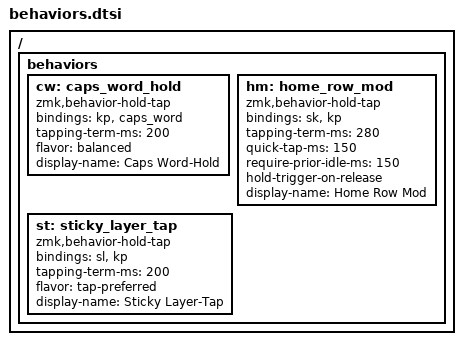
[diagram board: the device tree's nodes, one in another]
/ {
    behaviors {
        cw: caps_word_hold {
            compatible = "zmk,behavior-hold-tap";
            bindings = <&kp>, <&caps_word>;
            #binding-cells = <2>;
            tapping-term-ms = <200>;
            flavor = "balanced";
            display-name = "Caps Word-Hold";
        };

        hm: home_row_mod {
            compatible = "zmk,behavior-hold-tap";
            bindings = <&sk>, <&kp>;
            #binding-cells = <2>;
            tapping-term-ms = <280>;
            quick-tap-ms = <150>;
            require-prior-idle-ms = <150>;
            hold-trigger-on-release;
            display-name = "Home Row Mod";
        };

        st: sticky_layer_tap {
            compatible = "zmk,behavior-hold-tap";
            bindings = <&sl>, <&kp>;
            #binding-cells = <2>;
            tapping-term-ms = <200>;
            flavor = "tap-preferred";
            display-name = "Sticky Layer-Tap";
        };
    };
};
